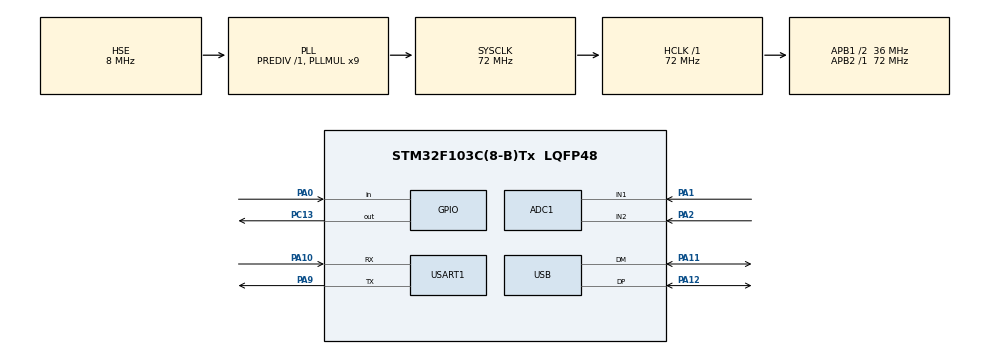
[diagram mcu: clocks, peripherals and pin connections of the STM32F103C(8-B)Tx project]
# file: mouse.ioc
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ADC1.Channel-0\#ChannelRegularConversion=ADC_CHANNEL_2
ADC1.Channel-1\#ChannelRegularConversion=ADC_CHANNEL_1
ADC1.ContinuousConvMode=ENABLE
ADC1.DataAlign=ADC_DATAALIGN_RIGHT
ADC1.InjNumberOfConversion=0
ADC1.NbrOfConversion=2
ADC1.NbrOfConversionFlag=1
ADC1.Rank-0\#ChannelRegularConversion=1
ADC1.Rank-1\#ChannelRegularConversion=2
ADC1.SamplingTime-0\#ChannelRegularConversion=ADC_SAMPLETIME_71CYCLES_5
ADC1.SamplingTime-1\#ChannelRegularConversion=ADC_SAMPLETIME_71CYCLES_5
ADC1.master=1
Dma.ADC1.0.Direction=DMA_PERIPH_TO_MEMORY
Dma.ADC1.0.Instance=DMA1_Channel1
Dma.ADC1.0.MemDataAlignment=DMA_MDATAALIGN_HALFWORD
Dma.ADC1.0.MemInc=DMA_MINC_ENABLE
Dma.ADC1.0.Mode=DMA_CIRCULAR
Dma.ADC1.0.PeriphDataAlignment=DMA_PDATAALIGN_HALFWORD
Dma.ADC1.0.PeriphInc=DMA_PINC_DISABLE
Dma.ADC1.0.Priority=DMA_PRIORITY_LOW
Dma.Request0=ADC1
Mcu.Family=STM32F1
Mcu.Name=STM32F103C(8-B)Tx
Mcu.Package=LQFP48
NVIC.ADC1_2_IRQn=true\:0\:0\:false\:false\:true\:true\:true
NVIC.DMA1_Channel1_IRQn=true\:0\:0\:false\:false\:true\:false\:true
NVIC.PriorityGroup=NVIC_PRIORITYGROUP_4
NVIC.USB_LP_CAN1_RX0_IRQn=true\:2\:0\:true\:false\:true\:false\:true
PA0-WKUP.GPIO_PuPd=GPIO_PULLUP
PA0-WKUP.Signal=GPIO_Input
PA1.Signal=ADCx_IN1
PA10.Mode=Asynchronous
PA10.Signal=USART1_RX
PA11.Mode=Device
PA11.Signal=USB_DM
PA12.Mode=Device
PA12.Signal=USB_DP
PA13.Mode=Serial_Wire
PA13.Signal=SYS_JTMS-SWDIO
PA14.Mode=Serial_Wire
PA14.Signal=SYS_JTCK-SWCLK
PA2.Signal=ADCx_IN2
PA9.Mode=Asynchronous
PA9.Signal=USART1_TX
PC13-TAMPER-RTC.Signal=GPIO_Output
PD0-OSC_IN.Mode=HSE-External-Oscillator
PD0-OSC_IN.Signal=RCC_OSC_IN
PD1-OSC_OUT.Mode=HSE-External-Oscillator
PD1-OSC_OUT.Signal=RCC_OSC_OUT
ProjectManager.HeapSize=0x200
ProjectManager.StackSize=0x400
ProjectManager.TargetToolchain=STM32CubeIDE
RCC.ADCPresc=RCC_ADCPCLK2_DIV6
RCC.AHBFreq_Value=72000000
RCC.APB1CLKDivider=RCC_HCLK_DIV2
RCC.APB1Freq_Value=36000000
RCC.APB1TimFreq_Value=72000000
RCC.APB2Freq_Value=72000000
RCC.APB2TimFreq_Value=72000000
RCC.HCLKFreq_Value=72000000
RCC.PLLMUL=RCC_PLL_MUL9
RCC.SYSCLKFreq_VALUE=72000000
RCC.SYSCLKSource=RCC_SYSCLKSOURCE_PLLCLK
RCC.USBFreq_Value=48000000
RCC.USBPrescaler=RCC_USBCLKSOURCE_PLL_DIV1_5
SH.ADCx_IN1.0=ADC1_IN1,IN1
SH.ADCx_IN2.0=ADC1_IN2,IN2
USART1.VirtualMode=VM_ASYNC
USB_DEVICE.CLASS_NAME_FS=HID
USB_DEVICE.VirtualMode=Hid
USB_DEVICE.VirtualModeFS=Hid_FS
VP_USB_DEVICE_VS_USB_DEVICE_HID_FS.Mode=HID_FS
board=custom

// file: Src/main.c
/* USER CODE BEGIN Header */
/**
  ******************************************************************************
  * @file           : main.c
  * @brief          : Main program body
  ******************************************************************************
  * @attention
  *
  * <h2><center>&copy; Copyright (c) 2019 STMicroelectronics.
  * All rights reserved.</center></h2>
  *
  * This software component is licensed by ST under BSD 3-Clause license,
  * the "License"; You may not use this file except in compliance with the
  * License. You may obtain a copy of the License at:
  *                        opensource.org/licenses/BSD-3-Clause
  *
  ******************************************************************************
  */
/* USER CODE END Header */

#include "main.h"
#include "usb_device.h"

/* USER CODE BEGIN PD */
#define CLICK_REPORT_SIZE 3
/* USER CODE END PD */

ADC_HandleTypeDef hadc1;
DMA_HandleTypeDef hdma_adc1;

UART_HandleTypeDef huart1;

void SystemClock_Config(void);
static void MX_GPIO_Init(void);
static void MX_DMA_Init(void);
static void MX_ADC1_Init(void);
static void MX_USART1_UART_Init(void);

/* USER CODE BEGIN 0 */
extern USBD_HandleTypeDef hUsbDeviceFS;
uint16_t adcBuffer[2];
/* USER CODE END 0 */

int main(void)
{
  /* USER CODE BEGIN 1 */
	int8_t click_report[CLICK_REPORT_SIZE] = {0};

  /* USER CODE END 1 */

  /* MCU Configuration--------------------------------------------------------*/

  /* Reset of all peripherals, Initializes the Flash interface and the Systick. */
  HAL_Init();

  /* Configure the system clock */
  SystemClock_Config();

  /* Initialize all configured peripherals */
  MX_GPIO_Init();
  MX_DMA_Init();
  MX_USB_DEVICE_Init();
  MX_ADC1_Init();
  MX_USART1_UART_Init();
  /* USER CODE BEGIN 2 */
  //HAL_ADC_Start_DMA(&hadc1, (uint32_t*)adcBuffer, 2);
  char temp[10];
  /* USER CODE END 2 */

  /* Infinite loop */
  while (1)
  {

    /* USER CODE BEGIN 3 */
      HAL_GPIO_TogglePin(GPIOC, GPIO_PIN_13);
//      click_report[0] = 0;
//      click_report[1] = (adcBuffer[0]/2);  // send button press
//      click_report[2] = (adcBuffer[1]/2);  // send button press
//      itoa(adcBuffer[0],temp, 10);
//      strcat(temp," ");
    HAL_UART_Transmit(&huart1,'0',1,100);
    for(int i = 0; i < 100; i++){
      HAL_UART_Transmit(&huart1,"a",1,100);
      HAL_Delay(50);
    }
//      itoa(adcBuffer[1],temp, 10);
//      strcat(temp,"\n");

//      HAL_UART_Transmit(&huart1,temp,strlen(temp),100);
//	  if(HAL_GPIO_ReadPin(GPIOA,GPIO_PIN_0) == GPIO_PIN_RESET){
//	        HAL_GPIO_WritePin(GPIOC, GPIO_PIN_13, GPIO_PIN_RESET);
//
//	        click_report[0] = 1;  // send button press
//
//
//
//	        HAL_Delay(50);
//
//	        click_report[0] = 0;  // send button release
//	        USBD_HID_SendReport(&hUsbDeviceFS, click_report, CLICK_REPORT_SIZE);
//
//	        HAL_Delay(200);
//
//	        HAL_GPIO_WritePin(GPIOC, GPIO_PIN_13, GPIO_PIN_RESET);
//	      }
//      HAL_Delay(50);
//	  USBD_HID_SendReport(&hUsbDeviceFS, click_report, CLICK_REPORT_SIZE);
  }
  /* USER CODE END 3 */
}

void SystemClock_Config(void)
{
  RCC_OscInitTypeDef RCC_OscInitStruct = {0};
  RCC_ClkInitTypeDef RCC_ClkInitStruct = {0};
  RCC_PeriphCLKInitTypeDef PeriphClkInit = {0};

  /** Initializes the CPU, AHB and APB busses clocks
  */
  RCC_OscInitStruct.OscillatorType = RCC_OSCILLATORTYPE_HSE;
  RCC_OscInitStruct.HSEState = RCC_HSE_ON;
  RCC_OscInitStruct.HSEPredivValue = RCC_HSE_PREDIV_DIV1;
  RCC_OscInitStruct.HSIState = RCC_HSI_ON;
  RCC_OscInitStruct.PLL.PLLState = RCC_PLL_ON;
  RCC_OscInitStruct.PLL.PLLSource = RCC_PLLSOURCE_HSE;
  RCC_OscInitStruct.PLL.PLLMUL = RCC_PLL_MUL9;
  if (HAL_RCC_OscConfig(&RCC_OscInitStruct) != HAL_OK)
  {
    Error_Handler();
  }
  /** Initializes the CPU, AHB and APB busses clocks
  */
  RCC_ClkInitStruct.ClockType = RCC_CLOCKTYPE_HCLK|RCC_CLOCKTYPE_SYSCLK
                              |RCC_CLOCKTYPE_PCLK1|RCC_CLOCKTYPE_PCLK2;
  RCC_ClkInitStruct.SYSCLKSource = RCC_SYSCLKSOURCE_PLLCLK;
  RCC_ClkInitStruct.AHBCLKDivider = RCC_SYSCLK_DIV1;
  RCC_ClkInitStruct.APB1CLKDivider = RCC_HCLK_DIV2;
  RCC_ClkInitStruct.APB2CLKDivider = RCC_HCLK_DIV1;

  if (HAL_RCC_ClockConfig(&RCC_ClkInitStruct, FLASH_LATENCY_2) != HAL_OK)
  {
    Error_Handler();
  }
  PeriphClkInit.PeriphClockSelection = RCC_PERIPHCLK_ADC|RCC_PERIPHCLK_USB;
  PeriphClkInit.AdcClockSelection = RCC_ADCPCLK2_DIV6;
  PeriphClkInit.UsbClockSelection = RCC_USBCLKSOURCE_PLL_DIV1_5;
  if (HAL_RCCEx_PeriphCLKConfig(&PeriphClkInit) != HAL_OK)
  {
    Error_Handler();
  }
}

static void MX_ADC1_Init(void)
{

  ADC_ChannelConfTypeDef sConfig = {0};

  /** Common config
  */
  hadc1.Instance = ADC1;
  hadc1.Init.ScanConvMode = ADC_SCAN_ENABLE;
  hadc1.Init.ContinuousConvMode = ENABLE;
  hadc1.Init.DiscontinuousConvMode = DISABLE;
  hadc1.Init.ExternalTrigConv = ADC_SOFTWARE_START;
  hadc1.Init.DataAlign = ADC_DATAALIGN_RIGHT;
  hadc1.Init.NbrOfConversion = 2;
  if (HAL_ADC_Init(&hadc1) != HAL_OK)
  {
    Error_Handler();
  }
  /** Configure Regular Channel
  */
  sConfig.Channel = ADC_CHANNEL_2;
  sConfig.Rank = ADC_REGULAR_RANK_1;
  sConfig.SamplingTime = ADC_SAMPLETIME_71CYCLES_5;
  if (HAL_ADC_ConfigChannel(&hadc1, &sConfig) != HAL_OK)
  {
    Error_Handler();
  }
  /** Configure Regular Channel
  */
  sConfig.Channel = ADC_CHANNEL_1;
  sConfig.Rank = ADC_REGULAR_RANK_2;
  if (HAL_ADC_ConfigChannel(&hadc1, &sConfig) != HAL_OK)
  {
    Error_Handler();
  }

}

static void MX_USART1_UART_Init(void)
{

  huart1.Instance = USART1;
  huart1.Init.BaudRate = 115200;
  huart1.Init.WordLength = UART_WORDLENGTH_8B;
  huart1.Init.StopBits = UART_STOPBITS_1;
  huart1.Init.Parity = UART_PARITY_NONE;
  huart1.Init.Mode = UART_MODE_TX_RX;
  huart1.Init.HwFlowCtl = UART_HWCONTROL_NONE;
  huart1.Init.OverSampling = UART_OVERSAMPLING_16;
  if (HAL_UART_Init(&huart1) != HAL_OK)
  {
    Error_Handler();
  }

}

static void MX_DMA_Init(void)
{

  /* DMA controller clock enable */
  __HAL_RCC_DMA1_CLK_ENABLE();

  /* DMA interrupt init */
  /* DMA1_Channel1_IRQn interrupt configuration */
  HAL_NVIC_SetPriority(DMA1_Channel1_IRQn, 0, 0);
  HAL_NVIC_EnableIRQ(DMA1_Channel1_IRQn);

}

static void MX_GPIO_Init(void)
{
  GPIO_InitTypeDef GPIO_InitStruct = {0};

  /* GPIO Ports Clock Enable */
  __HAL_RCC_GPIOC_CLK_ENABLE();
  __HAL_RCC_GPIOD_CLK_ENABLE();
  __HAL_RCC_GPIOA_CLK_ENABLE();

  /*Configure GPIO pin Output Level */
  HAL_GPIO_WritePin(GPIOC, GPIO_PIN_13, GPIO_PIN_RESET);

  /*Configure GPIO pin : PC13 */
  GPIO_InitStruct.Pin = GPIO_PIN_13;
  GPIO_InitStruct.Mode = GPIO_MODE_OUTPUT_PP;
  GPIO_InitStruct.Pull = GPIO_NOPULL;
  GPIO_InitStruct.Speed = GPIO_SPEED_FREQ_LOW;
  HAL_GPIO_Init(GPIOC, &GPIO_InitStruct);

  /*Configure GPIO pin : PA0 */
  GPIO_InitStruct.Pin = GPIO_PIN_0;
  GPIO_InitStruct.Mode = GPIO_MODE_INPUT;
  GPIO_InitStruct.Pull = GPIO_PULLUP;
  HAL_GPIO_Init(GPIOA, &GPIO_InitStruct);

}

void Error_Handler(void)
{
}

/************************ (C) COPYRIGHT STMicroelectronics *****END OF FILE****/
